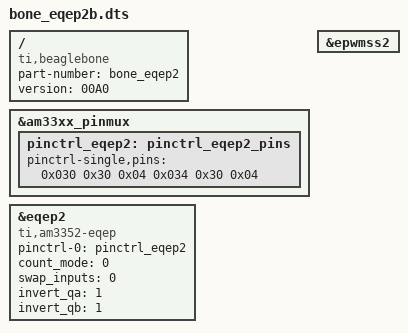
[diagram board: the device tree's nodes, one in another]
// SPDX-License-Identifier: GPL-2.0-only
/*
 * eQEP2 (alternate pins) overlay for BeagleBone (kernel 6.12+)
 *
 * This overlay configures the pinmux pads used by eQEP2 (alternate pinout)
 * and enables the EPWMSS2/eqep2 device. It targets kernels which declare
 * `#pinctrl-cells = <2>` (Debian 12 / kernel 6.12) so `pinctrl-single,pins`
 * must use the 3-cell format per pin: `<pad_offset config_flags mux_mode>`.
 *
 * Important notes (from project investigation):
 * - Use 3-cell entries: <offset config mux>. The final pad register value
 *   written by the driver is `config_flags | mux_mode` (e.g. 0x30 | 0x04 = 0x34).
 * - On kernel 6.12, attaching `pinctrl-0` directly to the `&eqep2` node may
 *   result in only one pin being claimed by the driver. To avoid this, this
 *   overlay applies the pinmux via `bone-pinmux-helper` under `&ocp` so the
 *   pin configuration is applied independently from the device probe order.
 * - These alternate pins avoid HDMI conflicts on some boards.
 *
 * Pad offsets (from original overlay):
 *  - P8_12 = conf_xxx = 0x030  (EQEP2A, MODE4)
 *  - P8_11 = conf_xxx = 0x034  (EQEP2B, MODE4)
 *  - P8_16 = conf_xxx = 0x038  (EQEP2_index, MODE4)
 *  - P8_15 = conf_xxx = 0x03C  (EQEP2_strobe, MODE4)
 */

/dts-v1/;
/plugin/;

/*
 * Converted overlay: original 2-cell pin entries transformed to 3-cell
 * (<offset config_flags mux_mode>) preserving the original combined values.
 */

/ {
    compatible = "ti,beaglebone", "ti,beaglebone-black";

    /* identification */
    part-number = "bone_eqep2";
    version = "00A0";

    fragment@0 {
        target = <&am33xx_pinmux>;
        __overlay__ {
            pinctrl_eqep2: pinctrl_eqep2_pins {
                /* Converted entries:
                 * 0x038 0x24 -> 0x038 0x20 0x04
                 * 0x03C 0x24 -> 0x03C 0x20 0x04
                 * 0x030 0x34 -> 0x030 0x30 0x04
                 * 0x034 0x34 -> 0x034 0x30 0x04
                 */
                pinctrl-single,pins = <
                    /*0x038 0x20 0x04*/  /* P8_16 = EQEP2_index, MODE4 (0x24 -> 0x20+0x04) */
                    /*0x03C 0x20 0x04*/  /* P8_15 = EQEP2_strobe, MODE4 (0x24 -> 0x20+0x04) */
                    0x030 0x30 0x04  /* P8_12 = EQEP2A_in, MODE4 (0x34 -> 0x30+0x04) */
                    0x034 0x30 0x04  /* P8_11 = EQEP2B_in, MODE4 (0x34 -> 0x30+0x04) */
                >;
            };
        };
    };

    fragment@1 {
        target = <&epwmss2>;
        __overlay__ {
            status = "okay";
        };
    };

    fragment@2 {
        target = <&eqep2>;
        __overlay__ {
            compatible = "ti,am3352-eqep";
            pinctrl-names = "default";
            pinctrl-0 = <&pinctrl_eqep2>;

            count_mode = <0>;
            swap_inputs = <0>;
            invert_qa = <1>;
            invert_qb = <1>;
            /*invert_qi = <0>;*/
            /*invert_qs = <0>;*/

            status = "okay";
        };
    };
};
